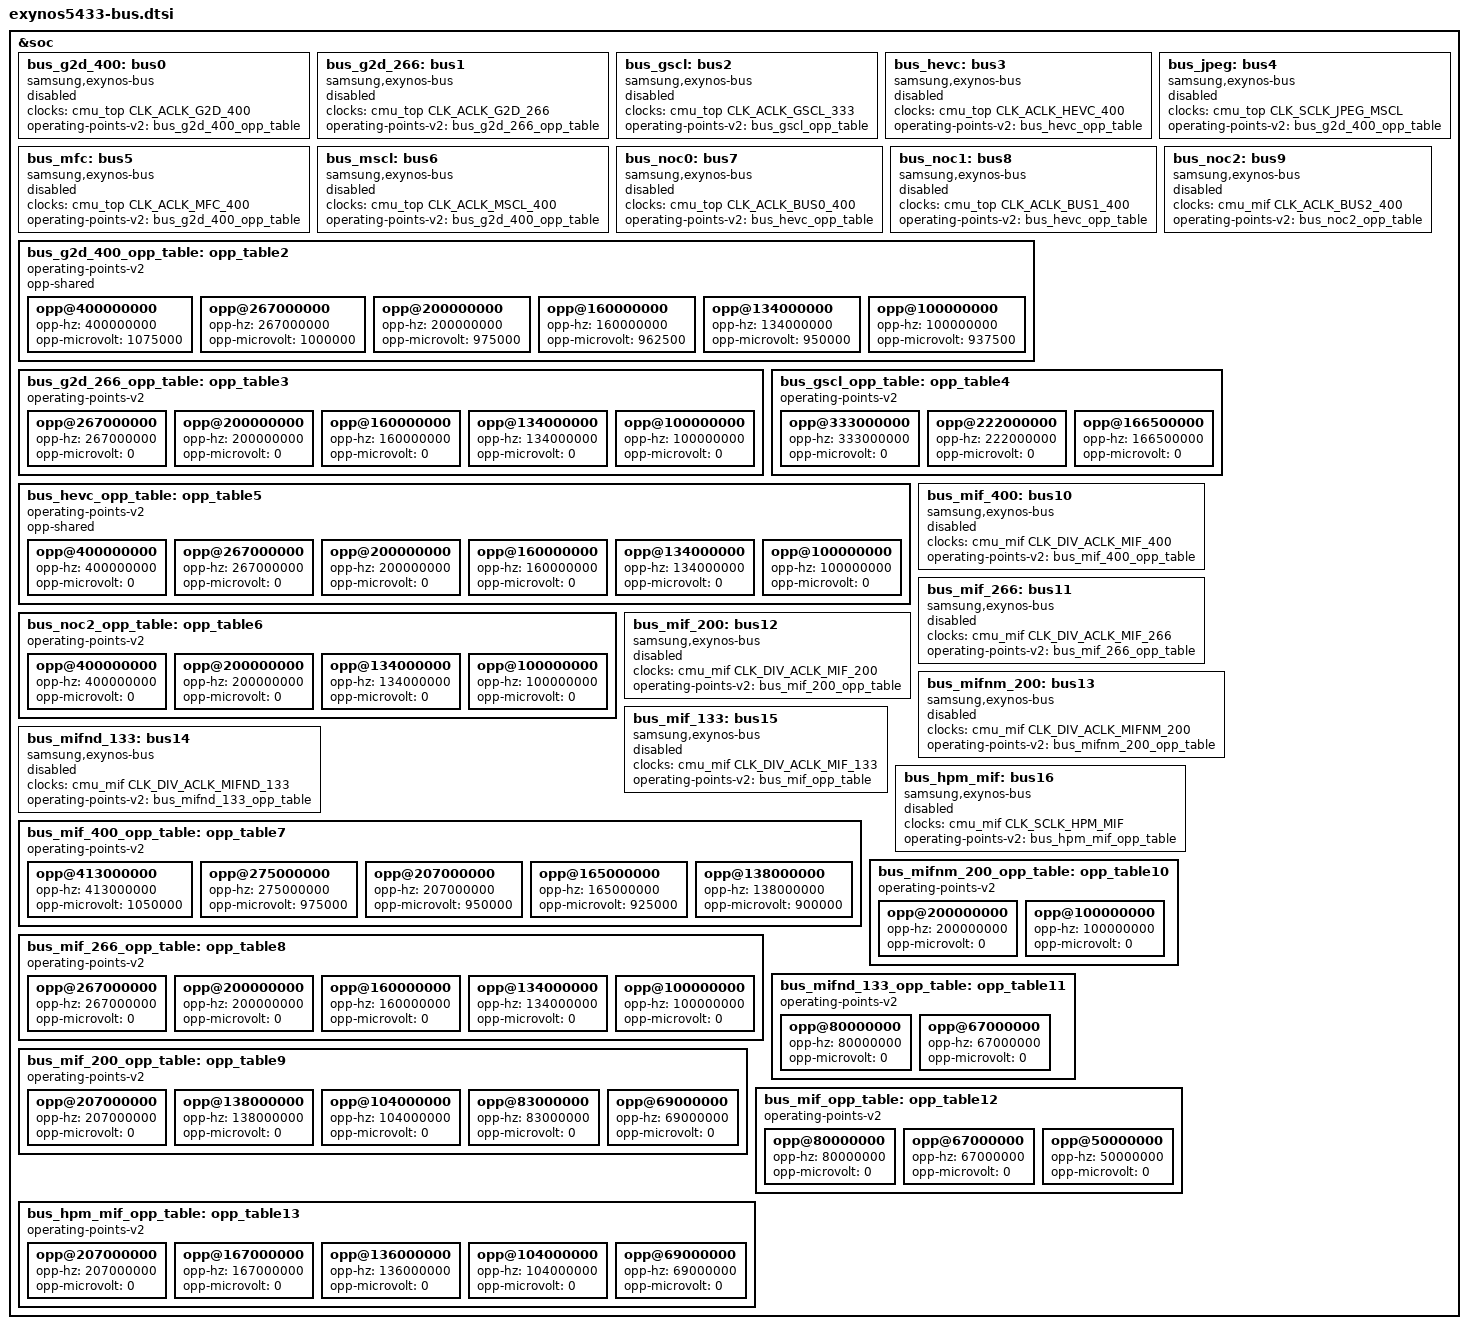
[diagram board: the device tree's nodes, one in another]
/*
 * Samsung's Exynos5433 SoC Memory interface and AMBA bus device tree source
 *
 * Copyright (c) 2016 Samsung Electronics Co., Ltd.
 * Chanwoo Choi <cw00.choi@samsung.com>
 *
 * This program is free software; you can redistribute it and/or modify
 * it under the terms of the GNU General Public License version 2 as
 * published by the Free Software Foundation.
 */

&soc {
	/* INT (Internal) block */
	bus_g2d_400: bus0 {
		compatible = "samsung,exynos-bus";
		clocks = <&cmu_top CLK_ACLK_G2D_400>;
		clock-names = "bus";
		operating-points-v2 = <&bus_g2d_400_opp_table>;
		status = "disabled";
	};

	bus_g2d_266: bus1 {
		compatible = "samsung,exynos-bus";
		clocks = <&cmu_top CLK_ACLK_G2D_266>;
		clock-names = "bus";
		operating-points-v2 = <&bus_g2d_266_opp_table>;
		status = "disabled";
	};

	bus_gscl: bus2 {
		compatible = "samsung,exynos-bus";
		clocks = <&cmu_top CLK_ACLK_GSCL_333>;
		clock-names = "bus";
		operating-points-v2 = <&bus_gscl_opp_table>;
		status = "disabled";
	};

	bus_hevc: bus3 {
		compatible = "samsung,exynos-bus";
		clocks = <&cmu_top CLK_ACLK_HEVC_400>;
		clock-names = "bus";
		operating-points-v2 = <&bus_hevc_opp_table>;
		status = "disabled";
	};

	bus_jpeg: bus4 {
		compatible = "samsung,exynos-bus";
		clocks = <&cmu_top CLK_SCLK_JPEG_MSCL>;
		clock-names = "bus";
		operating-points-v2 = <&bus_g2d_400_opp_table>;
		status = "disabled";
	};

	bus_mfc: bus5 {
		compatible = "samsung,exynos-bus";
		clocks = <&cmu_top CLK_ACLK_MFC_400>;
		clock-names = "bus";
		operating-points-v2 = <&bus_g2d_400_opp_table>;
		status = "disabled";
	};

	bus_mscl: bus6 {
		compatible = "samsung,exynos-bus";
		clocks = <&cmu_top CLK_ACLK_MSCL_400>;
		clock-names = "bus";
		operating-points-v2 = <&bus_g2d_400_opp_table>;
		status = "disabled";
	};

	bus_noc0: bus7 {
		compatible = "samsung,exynos-bus";
		clocks = <&cmu_top CLK_ACLK_BUS0_400>;
		clock-names = "bus";
		operating-points-v2 = <&bus_hevc_opp_table>;
		status = "disabled";
	};

	bus_noc1: bus8 {
		compatible = "samsung,exynos-bus";
		clocks = <&cmu_top CLK_ACLK_BUS1_400>;
		clock-names = "bus";
		operating-points-v2 = <&bus_hevc_opp_table>;
		status = "disabled";
	};

	bus_noc2: bus9 {
		compatible = "samsung,exynos-bus";
		clocks = <&cmu_mif CLK_ACLK_BUS2_400>;
		clock-names = "bus";
		operating-points-v2 = <&bus_noc2_opp_table>;
		status = "disabled";
	};

	bus_g2d_400_opp_table: opp_table2 {
		compatible = "operating-points-v2";
		opp-shared;

		opp@400000000 {
			opp-hz = /bits/ 64 <400000000>;
			opp-microvolt = <1075000>;
		};
		opp@267000000 {
			opp-hz = /bits/ 64 <267000000>;
			opp-microvolt = <1000000>;
		};
		opp@200000000 {
			opp-hz = /bits/ 64 <200000000>;
			opp-microvolt = <975000>;
		};
		opp@160000000 {
			opp-hz = /bits/ 64 <160000000>;
			opp-microvolt = <962500>;
		};
		opp@134000000 {
			opp-hz = /bits/ 64 <134000000>;
			opp-microvolt = <950000>;
		};
		opp@100000000 {
			opp-hz = /bits/ 64 <100000000>;
			opp-microvolt = <937500>;
		};
	};

	bus_g2d_266_opp_table: opp_table3 {
		compatible = "operating-points-v2";

		opp@267000000 {
			opp-hz = /bits/ 64 <267000000>;
			opp-microvolt = <0>;
		};
		opp@200000000 {
			opp-hz = /bits/ 64 <200000000>;
			opp-microvolt = <0>;
		};
		opp@160000000 {
			opp-hz = /bits/ 64 <160000000>;
			opp-microvolt = <0>;
		};
		opp@134000000 {
			opp-hz = /bits/ 64 <134000000>;
			opp-microvolt = <0>;
		};
		opp@100000000 {
			opp-hz = /bits/ 64 <100000000>;
			opp-microvolt = <0>;
		};
	};

	bus_gscl_opp_table: opp_table4 {
		compatible = "operating-points-v2";

		opp@333000000 {
			opp-hz = /bits/ 64 <333000000>;
			opp-microvolt = <0>;
		};
		opp@222000000 {
			opp-hz = /bits/ 64 <222000000>;
			opp-microvolt = <0>;
		};
		opp@166500000 {
			opp-hz = /bits/ 64 <166500000>;
			opp-microvolt = <0>;
		};
	};

	bus_hevc_opp_table: opp_table5 {
		compatible = "operating-points-v2";
		opp-shared;

		opp@400000000 {
			opp-hz = /bits/ 64 <400000000>;
			opp-microvolt = <0>;
		};
		opp@267000000 {
			opp-hz = /bits/ 64 <267000000>;
			opp-microvolt = <0>;
		};
		opp@200000000 {
			opp-hz = /bits/ 64 <200000000>;
			opp-microvolt = <0>;
		};
		opp@160000000 {
			opp-hz = /bits/ 64 <160000000>;
			opp-microvolt = <0>;
		};
		opp@134000000 {
			opp-hz = /bits/ 64 <134000000>;
			opp-microvolt = <0>;
		};
		opp@100000000 {
			opp-hz = /bits/ 64 <100000000>;
			opp-microvolt = <0>;
		};
	};

	bus_noc2_opp_table: opp_table6 {
		compatible = "operating-points-v2";

		opp@400000000 {
			opp-hz = /bits/ 64 <400000000>;
			opp-microvolt = <0>;
		};
		opp@200000000 {
			opp-hz = /bits/ 64 <200000000>;
			opp-microvolt = <0>;
		};
		opp@134000000 {
			opp-hz = /bits/ 64 <134000000>;
			opp-microvolt = <0>;
		};
		opp@100000000 {
			opp-hz = /bits/ 64 <100000000>;
			opp-microvolt = <0>;
		};
	};

	/* MIF (Memory Interface) block*/
	bus_mif_400: bus10 {
		compatible = "samsung,exynos-bus";
		clocks = <&cmu_mif CLK_DIV_ACLK_MIF_400>;
		clock-names = "bus";
		operating-points-v2 = <&bus_mif_400_opp_table>;
		status = "disabled";
	};

	bus_mif_266: bus11 {
		compatible = "samsung,exynos-bus";
		clocks = <&cmu_mif CLK_DIV_ACLK_MIF_266>;
		clock-names = "bus";
		operating-points-v2 = <&bus_mif_266_opp_table>;
		status = "disabled";
	};

	bus_mif_200: bus12 {
		compatible = "samsung,exynos-bus";
		clocks = <&cmu_mif CLK_DIV_ACLK_MIF_200>;
		clock-names = "bus";
		operating-points-v2 = <&bus_mif_200_opp_table>;
		status = "disabled";
	};

	bus_mifnm_200: bus13 {
		compatible = "samsung,exynos-bus";
		clocks = <&cmu_mif CLK_DIV_ACLK_MIFNM_200>;
		clock-names = "bus";
		operating-points-v2 = <&bus_mifnm_200_opp_table>;
		status = "disabled";
	};

	bus_mifnd_133: bus14 {
		compatible = "samsung,exynos-bus";
		clocks = <&cmu_mif CLK_DIV_ACLK_MIFND_133>;
		clock-names = "bus";
		operating-points-v2 = <&bus_mifnd_133_opp_table>;
		status = "disabled";
	};

	bus_mif_133: bus15 {
		compatible = "samsung,exynos-bus";
		clocks = <&cmu_mif CLK_DIV_ACLK_MIF_133>;
		clock-names = "bus";
		operating-points-v2 = <&bus_mif_opp_table>;
		status = "disabled";
	};

	bus_hpm_mif: bus16 {
		compatible = "samsung,exynos-bus";
		clocks = <&cmu_mif CLK_SCLK_HPM_MIF>;
		clock-names = "bus";
		operating-points-v2 = <&bus_hpm_mif_opp_table>;
		status = "disabled";
	};

	bus_mif_400_opp_table: opp_table7 {
		compatible = "operating-points-v2";

		opp@413000000 {
			opp-hz = /bits/ 64 <413000000>;
			opp-microvolt = <1050000>;
		};
		opp@275000000 {
			opp-hz = /bits/ 64 <275000000>;
			opp-microvolt = <975000>;
		};
		opp@207000000 {
			opp-hz = /bits/ 64 <207000000>;
			opp-microvolt = <950000>;
		};
		opp@165000000 {
			opp-hz = /bits/ 64 <165000000>;
			opp-microvolt = <925000>;
		};
		opp@138000000 {
			opp-hz = /bits/ 64 <138000000>;
			opp-microvolt = <900000>;
		};
	};

	bus_mif_266_opp_table: opp_table8 {
		compatible = "operating-points-v2";

		opp@267000000 {
			opp-hz = /bits/ 64 <267000000>;
			opp-microvolt = <0>;
		};
		opp@200000000 {
			opp-hz = /bits/ 64 <200000000>;
			opp-microvolt = <0>;
		};
		opp@160000000 {
			opp-hz = /bits/ 64 <160000000>;
			opp-microvolt = <0>;
		};
		opp@134000000 {
			opp-hz = /bits/ 64 <134000000>;
			opp-microvolt = <0>;
		};
		opp@100000000 {
			opp-hz = /bits/ 64 <100000000>;
			opp-microvolt = <0>;
		};
	};

	bus_mif_200_opp_table: opp_table9 {
		compatible = "operating-points-v2";

		opp@207000000 {
			opp-hz = /bits/ 64 <207000000>;
			opp-microvolt = <0>;
		};
		opp@138000000 {
			opp-hz = /bits/ 64 <138000000>;
			opp-microvolt = <0>;
		};
		opp@104000000 {
			opp-hz = /bits/ 64 <104000000>;
			opp-microvolt = <0>;
		};
		opp@83000000 {
			opp-hz = /bits/ 64 <83000000>;
			opp-microvolt = <0>;
		};
		opp@69000000 {
			opp-hz = /bits/ 64 <69000000>;
			opp-microvolt = <0>;
		};
	};

	bus_mifnm_200_opp_table: opp_table10 {
		compatible = "operating-points-v2";

		opp@200000000 {
			opp-hz = /bits/ 64 <200000000>;
			opp-microvolt = <0>;
		};
		opp@100000000 {
			opp-hz = /bits/ 64 <100000000>;
			opp-microvolt = <0>;
		};
	};

	bus_mifnd_133_opp_table: opp_table11 {
		compatible = "operating-points-v2";

		opp@80000000 {
			opp-hz = /bits/ 64 <80000000>;
			opp-microvolt = <0>;
		};
		opp@67000000 {
			opp-hz = /bits/ 64 <67000000>;
			opp-microvolt = <0>;
		};
	};

	bus_mif_opp_table: opp_table12 {
		compatible = "operating-points-v2";

		opp@80000000 {
			opp-hz = /bits/ 64 <80000000>;
			opp-microvolt = <0>;
		};
		opp@67000000 {
			opp-hz = /bits/ 64 <67000000>;
			opp-microvolt = <0>;
		};
		opp@50000000 {
			opp-hz = /bits/ 64 <50000000>;
			opp-microvolt = <0>;
		};
	};

	bus_hpm_mif_opp_table: opp_table13 {
		compatible = "operating-points-v2";

		opp@207000000 {
			opp-hz = /bits/ 64 <207000000>;
			opp-microvolt = <0>;
		};
		opp@167000000 {
			opp-hz = /bits/ 64 <167000000>;
			opp-microvolt = <0>;
		};
		opp@136000000 {
			opp-hz = /bits/ 64 <136000000>;
			opp-microvolt = <0>;
		};
		opp@104000000 {
			opp-hz = /bits/ 64 <104000000>;
			opp-microvolt = <0>;
		};
		opp@69000000 {
			opp-hz = /bits/ 64 <69000000>;
			opp-microvolt = <0>;
		};
	};
};
